# STM32F100xB register map
File version: 1.0
Registers are 32-bit, read-write, reset 0x0 unless marked. A register's access mark holds for its fields unless they carry their own. Offsets are from the block's base; [hi:lo] are bit positions; {n}, {i} and the like mark numbered series; 'fields as' and 'values as' point back to an identical list.

## CEC — Consumer Electronics Control (CEC)
Base 0x40007800
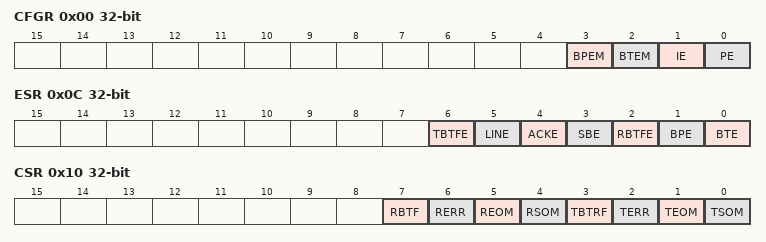
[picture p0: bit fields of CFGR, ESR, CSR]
0x00 CFGR
  [3] BPEM — Bit Period Error Mode
  [2] BTEM — Bit Timing Error Mode
  [1] IE — Interrupt Enable
  [0] PE — Peripheral Enable
0x04 OAR
  [3:0] OA — OA[3:0]: Own Address
0x08 PRES
  [13:0] PRES — Prescaler Counter Value
0x0C ESR
  [6] TBTFE — Tx Block Transfer Finished Error
  [5] LINE — Line Error
  [4] ACKE — Block Acknowledge Error
  [3] SBE — Start Bit Error
  [2] RBTFE — Rx Block Transfer Finished Error
  [1] BPE — Bit Period Error
  [0] BTE — Bit Timing Error
0x10 CSR
  [7] RBTF — Rx Block Transfer Finished
  [6] RERR — Rx Error
  [5] REOM — Rx End Of Message
  [4] RSOM — Rx Start Of Message
  [3] TBTRF — Tx Byte Transfer Request or Block Transfer Finished
  [2] TERR — Tx Error
  [1] TEOM — Tx End Of Message
  [0] TSOM — Tx Start Of Message
0x14 TXD
  [7:0] TXD — Tx Data register
0x18 RXD
  [7:0] RXD — Rx Data register

## AFIO — Alternate Function I/O
Base 0x40010000
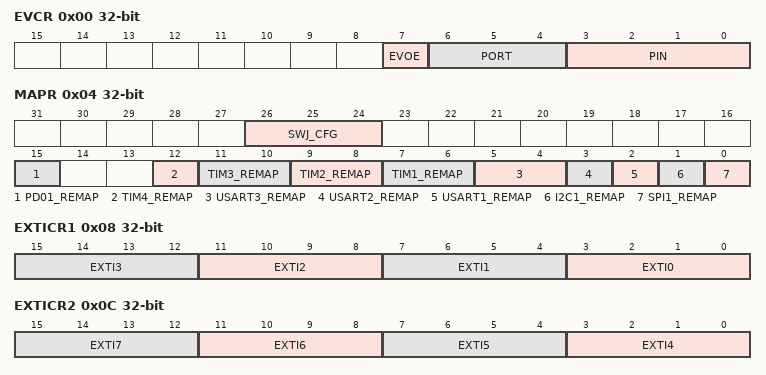
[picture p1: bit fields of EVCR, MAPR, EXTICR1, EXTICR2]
0x00 EVCR
  [7] EVOE — Event Output Enable
  [6:4] PORT — PORT[2:0] bits (Port selection)
  [3:0] PIN — PIN[3:0] bits (Pin selection)
0x04 MAPR
  [26:24] SWJ_CFG — SWJ_CFG[2:0] bits (Serial Wire JTAG configuration)
  [15] PD01_REMAP — Port D0/Port D1 mapping on OSC_IN/OSC_OUT
  [12] TIM4_REMAP — TIM4_REMAP bit (TIM4 remapping)
  [11:10] TIM3_REMAP — TIM3_REMAP[1:0] bits (TIM3 remapping)
  [9:8] TIM2_REMAP — TIM2_REMAP[1:0] bits (TIM2 remapping)
  [7:6] TIM1_REMAP — TIM1_REMAP[1:0] bits (TIM1 remapping)
  [5:4] USART3_REMAP — USART3_REMAP[1:0] bits (USART3 remapping)
  [3] USART2_REMAP — USART2 remapping
  [2] USART1_REMAP — USART1 remapping
  [1] I2C1_REMAP — I2C1 remapping
  [0] SPI1_REMAP — SPI1 remapping
0x08 EXTICR1
  [4n+3:4n] EXTI{n} (n=0..3) — EXTI {n} configuration
0x0C EXTICR2
  [4n-13:4n-16] EXTI{n} (n=4..7) — EXTI {n} configuration
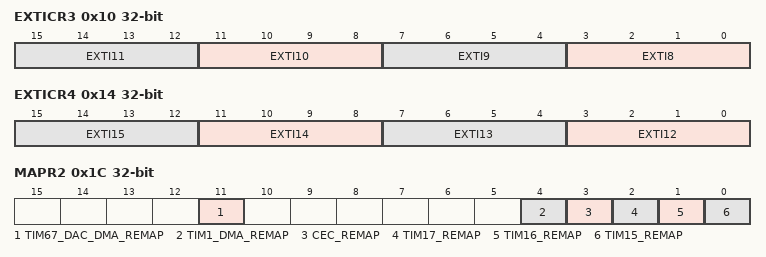
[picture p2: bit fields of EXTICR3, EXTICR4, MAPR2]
0x10 EXTICR3
  [4n-29:4n-32] EXTI{n} (n=8..11) — EXTI {n} configuration
0x14 EXTICR4
  [4n-45:4n-48] EXTI{n} (n=12..15) — EXTI {n} configuration
0x1C MAPR2
  [11] TIM67_DAC_DMA_REMAP — TIM6/TIM7 and DAC DMA remapping
  [4] TIM1_DMA_REMAP — TIM1_DMA remapping
  [3] CEC_REMAP — CEC remapping
  [2] TIM17_REMAP — TIM17 remapping
  [1] TIM16_REMAP — TIM16 remapping
  [0] TIM15_REMAP — TIM15 remapping

## EXTI — External Interrupt/Event Controller
Base 0x40010400
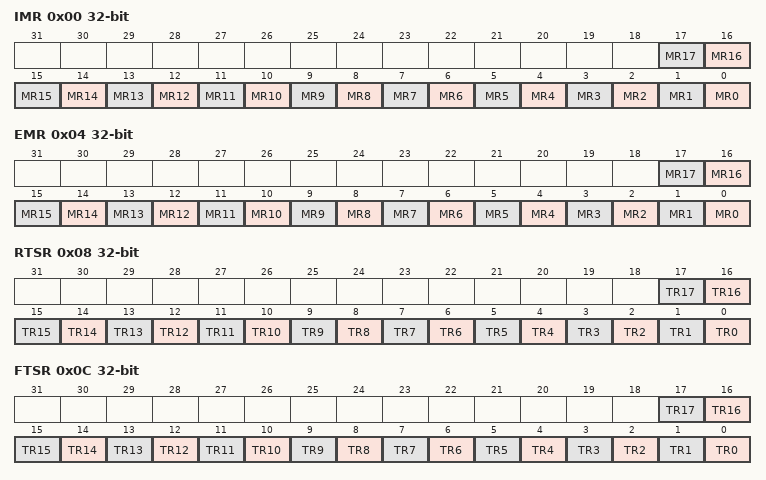
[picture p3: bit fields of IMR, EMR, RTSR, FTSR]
0x00 IMR
  [n] MR{n} (n=0..17) — Interrupt Mask on line {n}
0x04 EMR
  [n] MR{n} (n=0..17) — Event Mask on line {n}
0x08 RTSR
  [n] TR{n} (n=0..17) — Rising trigger event configuration bit of line {n}
0x0C FTSR
  [n] TR{n} (n=0..17) — Falling trigger event configuration bit of line {n}
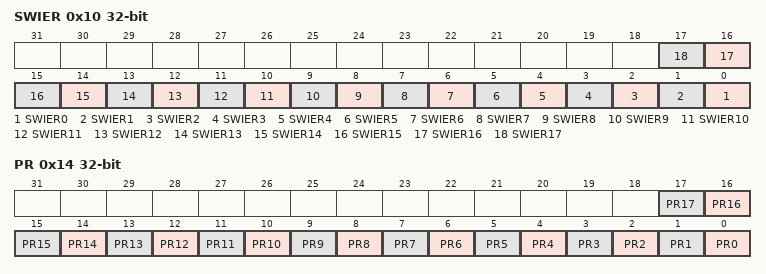
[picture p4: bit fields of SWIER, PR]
0x10 SWIER
  [n] SWIER{n} (n=0..17) — Software Interrupt on line {n}
0x14 PR
  [n] PR{n} (n=0..17) — Pending bit for line {n}

## GPIOA — General Purpose I/O
Base 0x40010800
Same registers: GPIOB 0x40010C00, GPIOC 0x40011000, GPIOD 0x40011400, GPIOE 0x40011800
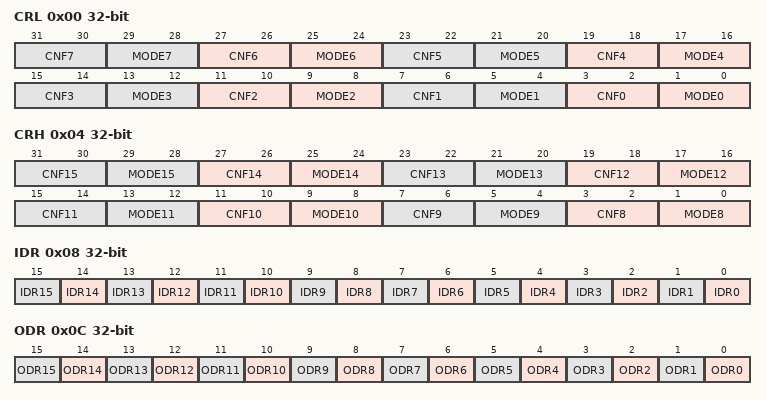
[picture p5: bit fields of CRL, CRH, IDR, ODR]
0x00 CRL
  [4n+3:4n+2] CNF{n} (n=0..7) — CNF{n}[1:0] bits (Port x configuration bits, pin {n})
  [4n+1:4n] MODE{n} (n=0..7) — MODE{n}[1:0] bits (Port x mode bits, pin {n})
0x04 CRH
  [4n-29:4n-30] CNF{n} (n=8..15) — CNF{n}[1:0] bits (Port x configuration bits, pin {n})
  [4n-31:4n-32] MODE{n} (n=8..15) — MODE{n}[1:0] bits (Port x mode bits, pin {n})
0x08 IDR
  [n] IDR{n} (n=0..15) — Port input data, bit {n}
0x0C ODR
  [n] ODR{n} (n=0..15) — Port output data, bit {n}
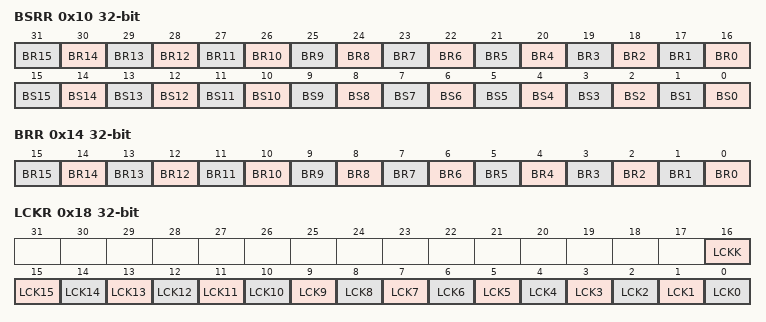
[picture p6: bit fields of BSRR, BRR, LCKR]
0x10 BSRR
  [n+16] BR{n} (n=0..15) — Port x Reset bit {n}
  [n] BS{n} (n=0..15) — Port x Set bit {n}
0x14 BRR
  [n] BR{n} (n=0..15) — Port x Reset bit {n}
0x18 LCKR
  [16] LCKK — Lock key
  [n] LCK{n} (n=0..15) — Port x Lock bit {n}

## DMA1
Base 0x40020000
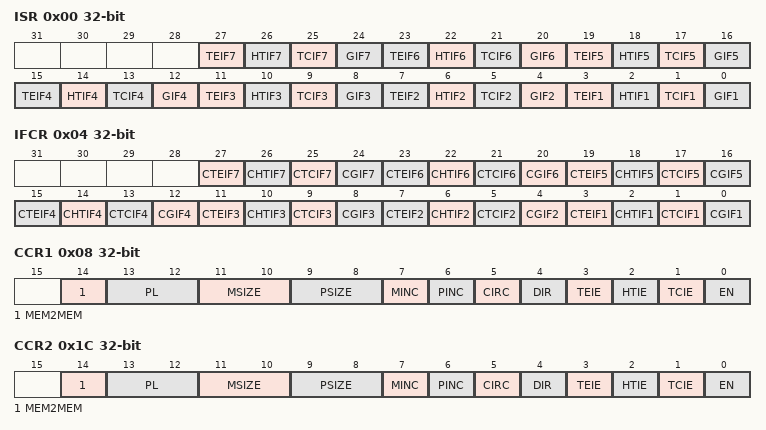
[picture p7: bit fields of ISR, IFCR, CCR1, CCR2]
0x00 ISR
  [4n-1] TEIF{n} (n=1..7) — Channel {n} Transfer Error flag
  [4n-2] HTIF{n} (n=1..7) — Channel {n} Half Transfer flag
  [4n-3] TCIF{n} (n=1..7) — Channel {n} Transfer Complete flag
  [4n-4] GIF{n} (n=1..7) — Channel {n} Global interrupt flag
0x04 IFCR
  [4n-1] CTEIF{n} (n=1..7) — Channel {n} Transfer Error clear
  [4n-2] CHTIF{n} (n=1..7) — Channel {n} Half Transfer clear
  [4n-3] CTCIF{n} (n=1..7) — Channel {n} Transfer Complete clear
  [4n-4] CGIF{n} (n=1..7) — Channel {n} Global interrupt clear
0x08 CCR1
  [14] MEM2MEM — Memory to memory mode
  [13:12] PL — PL[1:0] bits(Channel Priority level)
  [11:10] MSIZE — MSIZE[1:0] bits (Memory size)
  [9:8] PSIZE — PSIZE[1:0] bits (Peripheral size)
  [7] MINC — Memory increment mode
  [6] PINC — Peripheral increment mode
  [5] CIRC — Circular mode
  [4] DIR — Data transfer direction
  [3] TEIE — Transfer error interrupt enable
  [2] HTIE — Half Transfer interrupt enable
  [1] TCIE — Transfer complete interrupt enable
  [0] EN — Channel enable
0x0C CNDTR1
  [15:0] NDT — Number of data to Transfer
0x10 CPAR1
  [31:0] PA — Peripheral Address
{0x0+0x14*i} CMAR{i} (i=1..7)
  [31:0] MA — Memory Address
0x1C CCR2
  fields as CCR1
0x20 CNDTR2
  [15:0] NDT — Number of data to Transfer
0x24 CPAR2
  [31:0] PA — Peripheral Address
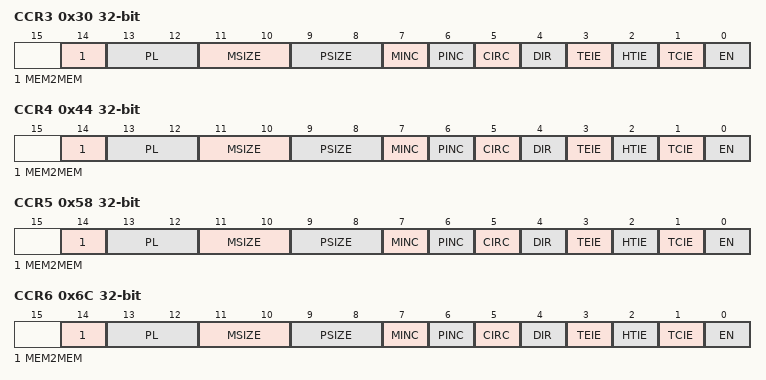
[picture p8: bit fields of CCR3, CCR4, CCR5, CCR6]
0x30 CCR3
  fields as CCR1
0x34 CNDTR3
  [15:0] NDT — Number of data to Transfer
0x38 CPAR3
  [31:0] PA — Peripheral Address
0x44 CCR4
  fields as CCR1
0x48 CNDTR4
  [15:0] NDT — Number of data to Transfer
0x4C CPAR4
  [31:0] PA — Peripheral Address
0x58 CCR5
  fields as CCR1
0x5C CNDTR5
  [15:0] NDT — Number of data to Transfer
0x60 CPAR5
  [31:0] PA — Peripheral Address
0x6C CCR6
  fields as CCR1
0x70 CNDTR6
  [15:0] NDT — Number of data to Transfer
0x74 CPAR6
  [31:0] PA — Peripheral Address
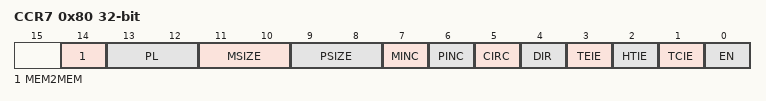
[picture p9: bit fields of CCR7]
0x80 CCR7
  fields as CCR1
0x84 CNDTR7
  [15:0] NDT — Number of data to Transfer
0x88 CPAR7
  [31:0] PA — Peripheral Address

## FLASH — FLASH Registers
Base 0x40022000
0x00 ACR
  [3] HLFCYA — Flash Half Cycle Access Enable
0x04 KEYR
  [31:0] FKEYR — FPEC Key
0x08 OPTKEYR
  [31:0] OPTKEYR — Option Byte Key
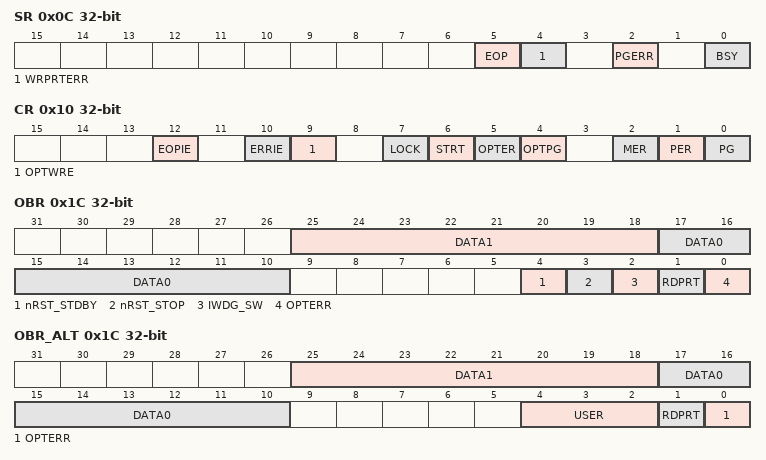
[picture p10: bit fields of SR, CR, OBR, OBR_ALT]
0x0C SR
  [5] EOP — End of operation
  [4] WRPRTERR — Write Protection Error
  [2] PGERR — Programming Error
  [0] BSY — Busy
0x10 CR
  [12] EOPIE — End of operation interrupt enable
  [10] ERRIE — Error Interrupt Enable
  [9] OPTWRE — Option Bytes Write Enable
  [7] LOCK
  [6] STRT — Start
  [5] OPTER — Option Byte Erase
  [4] OPTPG — Option Byte Programming
  [2] MER — Mass Erase
  [1] PER — Page Erase
  [0] PG — Programming
0x14 AR
  [31:0] FAR — Flash Address
0x1C OBR
  [25:18] DATA1
  [17:10] DATA0
  [4] nRST_STDBY
  [3] nRST_STOP
  [2] IWDG_SW
  [1] RDPRT — Read protection
  [0] OPTERR — Option Byte Error
0x1C OBR_ALT (alternate view of OBR)
  [25:18] DATA1
  [17:10] DATA0
  [4:2] USER — User Option Bytes
  [1] RDPRT — Read protection
  [0] OPTERR — Option Byte Error
0x20 WRPR
  [31:0] WRP — Write Protect

## CRC — CRC calculation unit
Base 0x40023000
0x00 DR — CRC Data register
  [31:0] DR — Data register bits
0x04 IDR 8-bit — CRC Independent data register
  [7:0] IDR — General-purpose 8-bit data register bits
0x08 CR — CRC Control register
  [0] RESET — RESET bit

## DBGMCU — Debug MCU
Base 0xE0042000
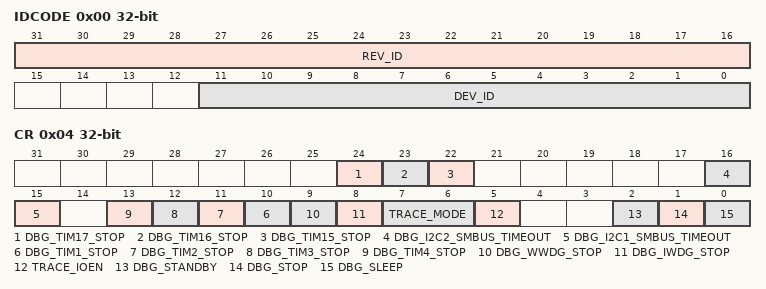
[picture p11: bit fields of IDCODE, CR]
0x00 IDCODE
  [31:16] REV_ID — REV_ID[15:0] bits (Revision Identifier)
  [11:0] DEV_ID — Device Identifier
0x04 CR
  [24] DBG_TIM17_STOP — Debug TIM17 stopped when Core is halted
  [23] DBG_TIM16_STOP — Debug TIM16 stopped when Core is halted
  [22] DBG_TIM15_STOP — Debug TIM15 stopped when Core is halted
  [16] DBG_I2C2_SMBUS_TIMEOUT — SMBUS timeout mode stopped when Core is halted
  [15] DBG_I2C1_SMBUS_TIMEOUT — SMBUS timeout mode stopped when Core is halted
  [n+9] DBG_TIM{n}_STOP (n=1..4) — TIM{n} counter stopped when core is halted
  [9] DBG_WWDG_STOP — Debug Window Watchdog stopped when Core is halted
  [8] DBG_IWDG_STOP — Debug Independent Watchdog stopped when Core is halted
  [7:6] TRACE_MODE — TRACE_MODE[1:0] bits (Trace Pin Assignment Control)
  [5] TRACE_IOEN — Trace Pin Assignment Control
  [2] DBG_STANDBY — Debug Standby mode
  [1] DBG_STOP — Debug Stop Mode
  [0] DBG_SLEEP — Debug Sleep Mode
